# PIC32MX254F128B register map
Vendor: Microchip
Registers are 32-bit, read-write, reset 0x0 unless marked. A register's access mark holds for its fields unless they carry their own. Addresses are absolute, and some are shared; only a register's first bit layout is shown; [hi:lo] are bit positions; {n}, {i} and the like mark numbered series; 'fields as' and 'values as' point back to an identical list.

## CONFIG — Configuration words, addresses in PhysicalSpace
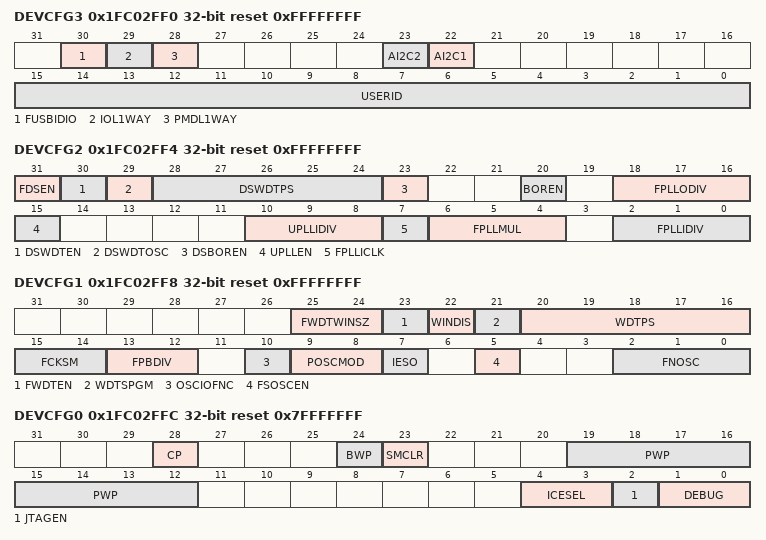
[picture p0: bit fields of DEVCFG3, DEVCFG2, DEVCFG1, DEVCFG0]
0x1FC02FF0 DEVCFG3 reset 0xFFFFFFFF
  [30] FUSBIDIO — USB USID Selection
    0=OFF (Controlled by Port Function); 1=ON (Controlled by the USB Module)
  [29] IOL1WAY — Peripheral Pin Select Configuration
    1=ON (Allow only one reconfiguration); 0=OFF (Allow multiple reconfigurations)
  [28] PMDL1WAY — Peripheral Module Disable Configuration
    values as IOL1WAY
  [23] AI2C2 — Alternate I/O Select for I2C2
    1=ON (I2C2 uses the ASDA2/ASCL2 pins); 0=OFF (I2C2 uses the SDA2/SCL2 pins)
  [22] AI2C1 — Alternate I/O Select for I2C1
    1=ON (I2C1 uses the ASDA1/ASCL1 pins); 0=OFF (I2C1 uses the SDA1/SCL1 pins)
  [15:0] USERID
0x1FC02FF4 DEVCFG2 reset 0xFFFFFFFF
  [31] FDSEN — Deep Sleep Enable
    0=OFF (Disable DSEN bit in DSCON); 1=ON (Enable DSEN bit in DSCON)
  [30] DSWDTEN — Deep Sleep Watchdog Timer Enable
    0=OFF (Disable DSWDT during Deep Sleep Mode); 1=ON (Enable DSWDT during Deep Sleep Mode)
  [29] DSWDTOSC — Deep Sleep WDT Reference Clock Selection
    0=SOSC (Select SOSC as DSWDT Reference Clock); 1=LPRC (Select LPRC as DSWDT Reference clock)
  [28:24] DSWDTPS — Deep Sleep Watchdog Timer Postscaler
    {v}=DSPS{v+1} (1:2^{v+5}) (v=0..31)
  [23] DSBOREN — Deep Sleep BOR Enable
    0=OFF (Disable ZPBOR during Deep Sleep Mode); 1=ON (Enable ZPBOR during Deep Sleep Mode)
  [20] BOREN — Brown-Out Reset (BOR) Enable
    0=OFF (Disable BOR); 1=ON (Enable BOR)
  [18:16] FPLLODIV — System PLL Output Clock Divider
    0=DIV_1 (PLL Divide by 1); 1=DIV_2 (PLL Divide by 2); 2=DIV_4 (PLL Divide by 4); 3=DIV_8 (PLL Divide by 8); 4=DIV_16 (PLL Divide by 16); 5=DIV_32 (PLL Divide by 32); 6=DIV_64 (PLL Divide by 64); 7=DIV_256 (PLL Divide by 256)
  [15] UPLLEN — USB PLL Enable
    0=ON (USB PLL Enabled); 1=OFF (USB PLL Disabled)
  [10:8] UPLLIDIV — USB PLL Input Divider
    {v}=DIV_{v+1} ({v+1}x Divider) (v=0..5); 6=DIV_10 (10x Divider); 7=DIV_12 (12x Divider)
  [7] FPLLICLK — System PLL Input Clock Selection
    0=PLL_POSC (POSC is input to the System PLL); 1=PLL_FRC (FRC is input to the System PLL)
  [6:4] FPLLMUL — PLL Multiplier
    {v}=MUL_{v+15} ({v+15}x Multiplier) (v=0..6); 7=MUL_24 (24x Multiplier)
  [2:0] FPLLIDIV — PLL Input Divider
    values as UPLLIDIV
0x1FC02FF8 DEVCFG1 reset 0xFFFFFFFF
  [25:24] FWDTWINSZ — Watchdog Timer Window Size
    0=WINSZ_75 (Window Size is 75%); 1=WINSZ_50 (Window Size is 50%); 2=WINSZ_37 (Window Size is 37.5%); 3=WINSZ_25 (Window Size is 25%)
  [23] FWDTEN — Watchdog Timer Enable
    0=OFF (WDT Disabled (SWDTEN Bit Controls)); 1=ON (WDT Enabled)
  [22] WINDIS — Watchdog Timer Window Enable
    0=ON (Watchdog Timer is in Window Mode); 1=OFF (Watchdog Timer is in Non-Window Mode)
  [21] WDTSPGM — Watchdog Timer Stop During Flash Programming
    1=ON (Watchdog Timer stops during Flash programming); 0=OFF (Watchdog Timer runs during Flash programming)
  [20:16] WDTPS — Watchdog Timer Postscaler
    0=PS1 (1:1); 1=PS2 (1:2); 2=PS4 (1:4); 3=PS8 (1:8); 4=PS16 (1:16); 5=PS32 (1:32); 6=PS64 (1:64); 7=PS128 (1:128); 8=PS256 (1:256); 9=PS512 (1:512); 10=PS1024 (1:1024); 11=PS2048 (1:2048); 12=PS4096 (1:4096); 13=PS8192 (1:8192); 14=PS16384 (1:16384); 15=PS32768 (1:32768); 0b1x000=PS65536 (1:65536); 0b1x001=PS131072 (1:131072); 0b1x010=PS262144 (1:262144); 0b1x011=PS524288 (1:524288); 0b1x1xx=PS1048576 (1:1048576)
  [15:14] FCKSM — Clock Switching and Monitor Selection
    0=CSECME (Clock Switch Enable, FSCM Enabled); 1=CSECMD (Clock Switch Enable, FSCM Disabled); 3=CSDCMD (Clock Switch Disable, FSCM Disabled)
  [13:12] FPBDIV — Peripheral Clock Divisor
    0=DIV_1 (Pb_Clk is Sys_Clk/1); 1=DIV_2 (Pb_Clk is Sys_Clk/2); 2=DIV_4 (Pb_Clk is Sys_Clk/4); 3=DIV_8 (Pb_Clk is Sys_Clk/8)
  [10] OSCIOFNC — CLKO Output Signal Active on the OSCO Pin
    1=OFF (Disabled); 0=ON (Enabled)
  [9:8] POSCMOD — Primary Oscillator Configuration
    0=EC (External clock mode); 1=XT (XT osc mode); 2=HS (HS osc mode); 3=OFF (Primary osc disabled)
  [7] IESO — Internal/External Switch Over
    0=OFF (Disabled); 1=ON (Enabled)
  [5] FSOSCEN — Secondary Oscillator Enable
    0=OFF (Disabled); 1=ON (Enabled)
  [2:0] FNOSC — Oscillator Selection Bits
    0=FRC (Fast RC Osc (FRC)); 1=SPLL (System PLL); 2=POSC (Primary Osc (HS,EC, XT)); 4=SOSC (Low Power Secondary Osc (SOSC)); 5=LPRC (Low Power RC Osc (LPRC))
0x1FC02FFC DEVCFG0 reset 0x7FFFFFFF
  [28] CP — Code Protect
    0=ON (Protection Enabled); 1=OFF (Protection Disabled)
  [24] BWP — Boot Flash Write Protect bit
    0=ON (Protection Enabled); 1=OFF (Protection Disabled)
  [23] SMCLR — Soft Master Clear Enable
    0=MCLR_POR (MCLR pin generates an emulated POR Reset); 1=MCLR_NORM (MCLR pin generates a normal system Reset)
  [19:12] PWP — Program Flash Write Protect
    255=OFF (Disable); 254=PWP4K (First 4K); 253=PWP8K (First 8K); 252=PWP12K (First 12K); 251=PWP16K (First 16K); 250=PWP20K (First 20K); 249=PWP24K (First 24K); 248=PWP28K (First 28K); 247=PWP32K (First 32K); 246=PWP36K (First 36K); 245=PWP40K (First 40K); 244=PWP44K (First 44K); 243=PWP48K (First 48K); 242=PWP52K (First 52K); 241=PWP56K (First 56K); 240=PWP60K (First 60K); 239=PWP64K (First 64K); 238=PWP68K (First 68K); 237=PWP72K (First 72K); 236=PWP76K (First 76K); 235=PWP80K (First 80K); 234=PWP84K (First 84K); 233=PWP88K (First 88K); 232=PWP92K (First 92K); 231=PWP96K (First 96K); 230=PWP100K (First 100K); 229=PWP104K (First 104K); 228=PWP108K (First 108K); 227=PWP112K (First 112K); 226=PWP116K (First 116K); 225=PWP120K (First 120K); 224=PWP124K (First 124K); 223=PWP128K (First 128K); 222=PWP132K (First 132K); 221=PWP136K (First 136K); 220=PWP140K (First 140K); 219=PWP144K (First 144K); 218=PWP148K (First 148K); 217=PWP152K (First 152K); 216=PWP156K (First 156K); 215=PWP160K (First 160K); 214=PWP164K (First 164K); 213=PWP168K (First 168K); 212=PWP172K (First 172K); 211=PWP176K (First 176K); 210=PWP180K (First 180K); 209=PWP184K (First 184K); 208=PWP188K (First 188K); 207=PWP192K (First 192K); 206=PWP196K (First 196K); 205=PWP200K (First 200K); 204=PWP204K (First 204K); 203=PWP208K (First 208K); 202=PWP212K (First 212K); 201=PWP216K (First 216K); 200=PWP220K (First 220K); 199=PWP224K (First 224K); 198=PWP228K (First 228K); 197=PWP232K (First 232K); 196=PWP236K (First 236K); 195=PWP240K (First 240K); 194=PWP244K (First 244K); 193=PWP248K (First 248K); 192=PWP252K (First 252K); 191=PWP256K (First 256K)
  [4:3] ICESEL — ICE/ICD Comm Channel Select
    3=ICS_PGx1 (Communicate on PGEC1/PGED1); 2=ICS_PGx2 (Communicate on PGEC2/PGED2); 1=ICS_PGx3 (Communicate on PGEC3/PGED3); 0=ICS_PGx4 (Communicate on PGEC4/PGED4)
  [2] JTAGEN — JTAG Enable
    1=ON (JTAG Port Enabled); 0=OFF (JTAG Disabled)
  [1:0] DEBUG — Background Debugger Enable
    0=ON (Debugger is Enabled); 3=OFF (Debugger is Disabled)
